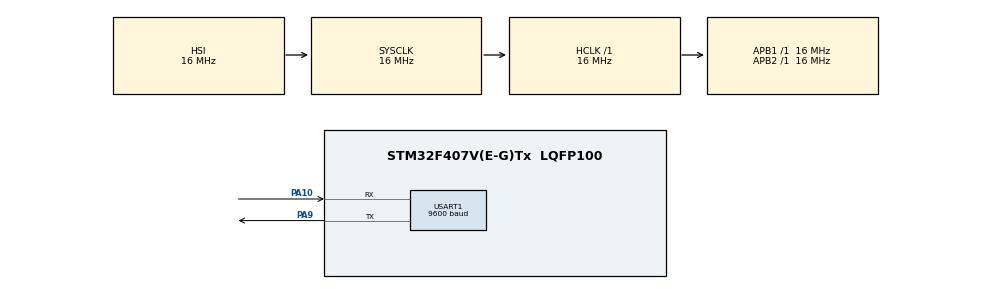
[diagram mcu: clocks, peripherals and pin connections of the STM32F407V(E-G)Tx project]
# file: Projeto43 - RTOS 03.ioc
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FREERTOS.BinarySemaphores01=myBinarySem01,Dynamic,NULL
FREERTOS.Tasks01=task1,24,128,task1_fun,Default,NULL,Dynamic,NULL,NULL;task2,24,128,task2_fun,Default,NULL,Dynamic,NULL,NULL
FREERTOS.configUSE_NEWLIB_REENTRANT=1
Mcu.Family=STM32F4
Mcu.Name=STM32F407V(E-G)Tx
Mcu.Package=LQFP100
NVIC.PriorityGroup=NVIC_PRIORITYGROUP_4
NVIC.TIM1_UP_TIM10_IRQn=true\:15\:0\:false\:false\:true\:false\:false\:true\:true
NVIC.TimeBase=TIM1_UP_TIM10_IRQn
NVIC.TimeBaseIP=TIM1
PA10.Mode=Asynchronous
PA10.Signal=USART1_RX
PA9.Mode=Asynchronous
PA9.Signal=USART1_TX
ProjectManager.HeapSize=0x200
ProjectManager.StackSize=0x400
ProjectManager.TargetToolchain=STM32CubeIDE
RCC.AHBFreq_Value=16000000
RCC.APB1Freq_Value=16000000
RCC.APB2Freq_Value=16000000
RCC.CortexFreq_Value=16000000
RCC.HSE_VALUE=25000000
RCC.HSI_VALUE=16000000
RCC.LSE_VALUE=32768
RCC.SYSCLKFreq_VALUE=16000000
RCC.VCOOutputFreq_Value=192000000
USART1.BaudRate=9600
USART1.Mode=MODE_TX
USART1.VirtualMode=VM_ASYNC
VP_FREERTOS_VS_CMSIS_V2.Mode=CMSIS_V2
VP_SYS_VS_tim1.Mode=TIM1
board=custom

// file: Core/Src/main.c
/* USER CODE BEGIN Header */
/**
  ******************************************************************************
  * @file           : main.c
  * @brief          : Main program body
  ******************************************************************************
  * @attention
  *
  * Copyright (c) 2023 STMicroelectronics.
  * All rights reserved.
  *
  * This software is licensed under terms that can be found in the LICENSE file
  * in the root directory of this software component.
  * If no LICENSE file comes with this software, it is provided AS-IS.
  *
  ******************************************************************************
  */
/* USER CODE END Header */
#include "main.h"
#include "cmsis_os.h"

/* USER CODE BEGIN Includes */

#include "string.h"

/* USER CODE END Includes */

 UART_HandleTypeDef huart1;

/* Definitions for task1 */
osThreadId_t task1Handle;
const osThreadAttr_t task1_attributes = {
  .name = "task1",
  .stack_size = 128 * 4,
  .priority = (osPriority_t) osPriorityNormal,
};
/* Definitions for task2 */
osThreadId_t task2Handle;
const osThreadAttr_t task2_attributes = {
  .name = "task2",
  .stack_size = 128 * 4,
  .priority = (osPriority_t) osPriorityNormal,
};
/* Definitions for myBinarySem01 */
osSemaphoreId_t myBinarySem01Handle;
const osSemaphoreAttr_t myBinarySem01_attributes = {
  .name = "myBinarySem01"
};

void SystemClock_Config(void);
static void MX_GPIO_Init(void);
static void MX_USART1_UART_Init(void);
void task1_fun(void *argument);
void task2_fun(void *argument);

int main(void)
{

  /* MCU Configuration--------------------------------------------------------*/

  /* Reset of all peripherals, Initializes the Flash interface and the Systick. */
  HAL_Init();

  /* Configure the system clock */
  SystemClock_Config();

  /* Initialize all configured peripherals */
  MX_GPIO_Init();
  MX_USART1_UART_Init();

  /* Init scheduler */
  osKernelInitialize();

  /* Create the semaphores(s) */
  /* creation of myBinarySem01 */
  myBinarySem01Handle = osSemaphoreNew(1, 0, &myBinarySem01_attributes);

  /* Create the thread(s) */
  /* creation of task1 */
  task1Handle = osThreadNew(task1_fun, NULL, &task1_attributes);

  /* creation of task2 */
  task2Handle = osThreadNew(task2_fun, NULL, &task2_attributes);

  /* USER CODE BEGIN RTOS_EVENTS */
  /* add events, ... */

  HAL_UART_Transmit(&huart1, (const uint8_t *) "Start...\r\n", strlen("Start...\r\n"), 100);
  HAL_Delay(2000);

  /* USER CODE END RTOS_EVENTS */

  /* Start scheduler */
  osKernelStart();

  /* We should never get here as control is now taken by the scheduler */
  /* Infinite loop */
  while (1)
  {

  }
}

void SystemClock_Config(void)
{
  RCC_OscInitTypeDef RCC_OscInitStruct = {0};
  RCC_ClkInitTypeDef RCC_ClkInitStruct = {0};

  /** Configure the main internal regulator output voltage
  */
  __HAL_RCC_PWR_CLK_ENABLE();
  __HAL_PWR_VOLTAGESCALING_CONFIG(PWR_REGULATOR_VOLTAGE_SCALE1);

  /** Initializes the RCC Oscillators according to the specified parameters
  * in the RCC_OscInitTypeDef structure.
  */
  RCC_OscInitStruct.OscillatorType = RCC_OSCILLATORTYPE_HSI;
  RCC_OscInitStruct.HSIState = RCC_HSI_ON;
  RCC_OscInitStruct.HSICalibrationValue = RCC_HSICALIBRATION_DEFAULT;
  RCC_OscInitStruct.PLL.PLLState = RCC_PLL_NONE;
  if (HAL_RCC_OscConfig(&RCC_OscInitStruct) != HAL_OK)
  {
    Error_Handler();
  }

  /** Initializes the CPU, AHB and APB buses clocks
  */
  RCC_ClkInitStruct.ClockType = RCC_CLOCKTYPE_HCLK|RCC_CLOCKTYPE_SYSCLK
                              |RCC_CLOCKTYPE_PCLK1|RCC_CLOCKTYPE_PCLK2;
  RCC_ClkInitStruct.SYSCLKSource = RCC_SYSCLKSOURCE_HSI;
  RCC_ClkInitStruct.AHBCLKDivider = RCC_SYSCLK_DIV1;
  RCC_ClkInitStruct.APB1CLKDivider = RCC_HCLK_DIV1;
  RCC_ClkInitStruct.APB2CLKDivider = RCC_HCLK_DIV1;

  if (HAL_RCC_ClockConfig(&RCC_ClkInitStruct, FLASH_LATENCY_0) != HAL_OK)
  {
    Error_Handler();
  }
}

static void MX_USART1_UART_Init(void)
{

  huart1.Instance = USART1;
  huart1.Init.BaudRate = 9600;
  huart1.Init.WordLength = UART_WORDLENGTH_8B;
  huart1.Init.StopBits = UART_STOPBITS_1;
  huart1.Init.Parity = UART_PARITY_NONE;
  huart1.Init.Mode = UART_MODE_TX;
  huart1.Init.HwFlowCtl = UART_HWCONTROL_NONE;
  huart1.Init.OverSampling = UART_OVERSAMPLING_16;
  if (HAL_UART_Init(&huart1) != HAL_OK)
  {
    Error_Handler();
  }

}

static void MX_GPIO_Init(void)
{

  /* GPIO Ports Clock Enable */
  __HAL_RCC_GPIOA_CLK_ENABLE();

}

void task1_fun(void *argument)
{
  /* USER CODE BEGIN 5 */
  /* Infinite loop */
  for(;;)
  {
	  static uint8_t count = 0;

	  HAL_UART_Transmit(&huart1, (const uint8_t *) "task1\r\n", strlen("task1\r\n"), 100);

	  if (count++ == 10)
	  {
		  osSemaphoreRelease(myBinarySem01Handle);
	  }

	  osDelay(1000);
  }
  /* USER CODE END 5 */
}

void task2_fun(void *argument)
{
  /* USER CODE BEGIN task2_fun */
  /* Infinite loop */
  for(;;)
  {
//	  osSemaphoreAcquire(myBinarySem01Handle, osWaitForever);
	  HAL_UART_Transmit(&huart1, (const uint8_t *) "task2\r\n", strlen("task2\r\n"), 100);
	  osSemaphoreAcquire(myBinarySem01Handle, 5000);
//	  osDelay(1000);
  }
  /* USER CODE END task2_fun */
}

void HAL_TIM_PeriodElapsedCallback(TIM_HandleTypeDef *htim)
{
  if (htim->Instance == TIM1) {
    HAL_IncTick();
  }
}

void Error_Handler(void)
{
  __disable_irq();
  while (1)
  {
  }
}
